# ATSAME53N20A register map
Vendor: Microchip Technology Inc.; Series: SAME53; File version: A
CPU: CM4 r0p1, little endian, MPU, FPU, 3 interrupt priority bits, 137 interrupts
Registers are 32-bit, read-write, reset 0x0 unless marked. A register's access mark holds for its fields unless they carry their own. Offsets are from the block's base; [hi:lo] are bit positions; 'fields as' and 'values as' point back to an identical list.

## SUPC — Supply Controller
Base 0x40001800; register names take the prefix SUPC_
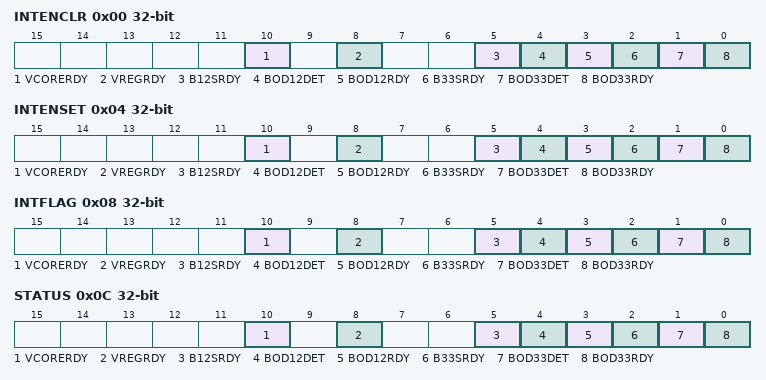
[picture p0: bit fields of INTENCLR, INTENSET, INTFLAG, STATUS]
0x00 INTENCLR — Interrupt Enable Clear
  [10] VCORERDY — VDDCORE Ready
  [8] VREGRDY — Voltage Regulator Ready
  [5] B12SRDY — BOD12 Synchronization Ready
  [4] BOD12DET — BOD12 Detection
  [3] BOD12RDY — BOD12 Ready
  [2] B33SRDY — BOD33 Synchronization Ready
  [1] BOD33DET — BOD33 Detection
  [0] BOD33RDY — BOD33 Ready
0x04 INTENSET — Interrupt Enable Set
  fields as INTENCLR
0x08 INTFLAG — Interrupt Flag Status and Clear
  fields as INTENCLR
0x0C STATUS ro — Power and Clocks Status
  fields as INTENCLR
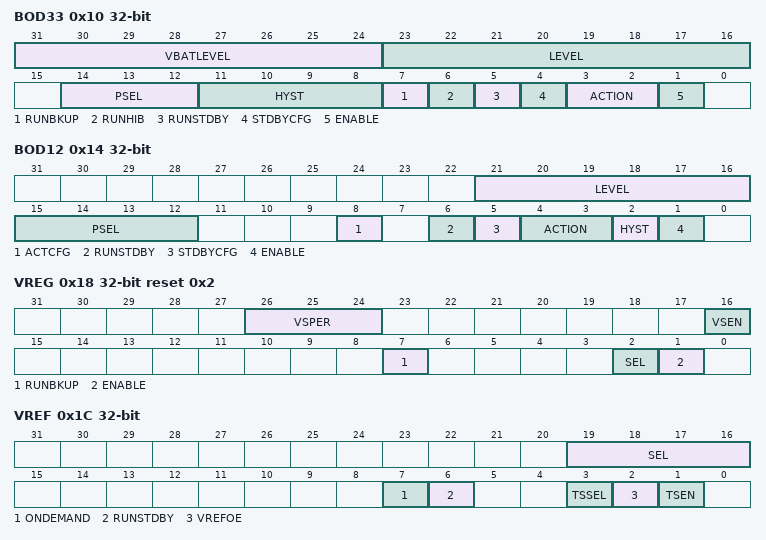
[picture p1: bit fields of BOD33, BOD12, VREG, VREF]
0x10 BOD33 — BOD33 Control
  [31:24] VBATLEVEL — Threshold Level in battery backup sleep mode for VBAT
  [23:16] LEVEL — Threshold Level for VDD
  [14:12] PSEL — Prescaler Select
    0=NODIV (Not divided); 1=DIV4 (Divide clock by 4); 2=DIV8 (Divide clock by 8); 3=DIV16 (Divide clock by 16); 4=DIV32 (Divide clock by 32); 5=DIV64 (Divide clock by 64); 6=DIV128 (Divide clock by 128); 7=DIV256 (Divide clock by 256)
  [11:8] HYST — Hysteresis value
  [7] RUNBKUP — Run in Backup mode
  [6] RUNHIB — Run in Hibernate mode
  [5] RUNSTDBY — Run in Standby mode
  [4] STDBYCFG — Configuration in Standby mode
  [3:2] ACTION — Action when Threshold Crossed
    0=NONE (No action); 1=RESET (The BOD33 generates a reset); 2=INT (The BOD33 generates an interrupt); 3=BKUP (The BOD33 puts the device in backup sleep mode)
  [1] ENABLE
0x14 BOD12 — BOD12 Control
  [21:16] LEVEL — Threshold Level
  [15:12] PSEL — Prescaler Select
    0=DIV2 (Divide clock by 2); 1=DIV4 (Divide clock by 4); 2=DIV8 (Divide clock by 8); 3=DIV16 (Divide clock by 16); 4=DIV32 (Divide clock by 32); 5=DIV64 (Divide clock by 64); 6=DIV128 (Divide clock by 128); 7=DIV256 (Divide clock by 256); 8=DIV512 (Divide clock by 512); 9=DIV1024 (Divide clock by 1024); 10=DIV2048 (Divide clock by 2048); 11=DIV4096 (Divide clock by 4096); 12=DIV8192 (Divide clock by 8192); 13=DIV16384 (Divide clock by 16384); 14=DIV32768 (Divide clock by 32768); 15=DIV65536 (Divide clock by 65536)
  [8] ACTCFG — Configuration in Active mode
  [6] RUNSTDBY — Run during Standby
  [5] STDBYCFG — Configuration in Standby mode
  [4:3] ACTION — Action when Threshold Crossed
    0=NONE (No action); 1=RESET (The BOD12 generates a reset); 2=INT (The BOD12 generates an interrupt)
  [2] HYST — Hysteresis Enable
  [1] ENABLE
0x18 VREG reset 0x2 — VREG Control
  [26:24] VSPER — Voltage Scaling Period
  [16] VSEN — Voltage Scaling Enable
  [7] RUNBKUP — Run in Backup mode
  [2] SEL — Voltage Regulator Selection
    0=LDO (LDO selection); 1=BUCK (Buck selection)
  [1] ENABLE
0x1C VREF — VREF Control
  [19:16] SEL — Voltage Reference Selection
    0=1V0 (1.0V voltage reference typical value); 1=1V1 (1.1V voltage reference typical value); 2=1V2 (1.2V voltage reference typical value); 3=1V25 (1.25V voltage reference typical value); 4=2V0 (2.0V voltage reference typical value); 5=2V2 (2.2V voltage reference typical value); 6=2V4 (2.4V voltage reference typical value); 7=2V5 (2.5V voltage reference typical value)
  [7] ONDEMAND — On Demand Contrl
  [6] RUNSTDBY — Run during Standby
  [3] TSSEL — Temperature Sensor Selection
  [2] VREFOE — Voltage Reference Output Enable
  [1] TSEN — Temperature Sensor Output Enable
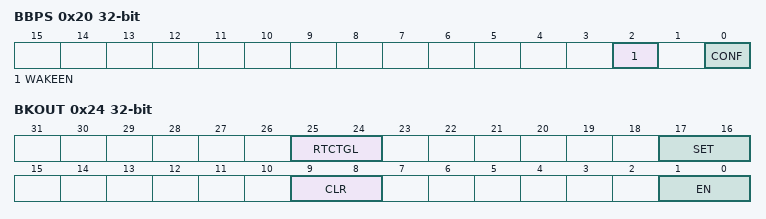
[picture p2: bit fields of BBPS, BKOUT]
0x20 BBPS — Battery Backup Power Switch
  [2] WAKEEN — Wake Enable
  [0] CONF — Battery Backup Configuration
    0=BOD33 (The power switch is handled by the BOD33); 1=FORCED (In Backup Domain, the backup domain is always supplied by battery backup power)
0x24 BKOUT — Backup Output Control
  [25:24] RTCTGL — RTC Toggle Output
  [17:16] SET wo — Set Output
  [9:8] CLR wo — Clear Output
  [1:0] EN — Enable Output
0x28 BKIN ro — Backup Input Control
  [7:0] BKIN — Backup Input Value
